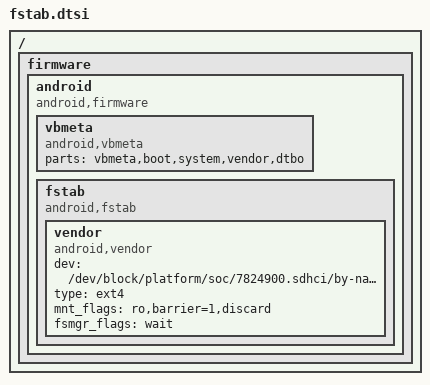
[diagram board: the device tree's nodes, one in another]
/ {
	/delete-node/ firmware;
	firmware: firmware {
		android {
			compatible = "android,firmware";
			vbmeta {
				compatible = "android,vbmeta";
				parts = "vbmeta,boot,system,vendor,dtbo";
			};

			fstab {
				compatible = "android,fstab";
				vendor {
					compatible = "android,vendor";
					dev = "/dev/block/platform/soc/7824900.sdhci/by-name/vendor";
					type = "ext4";
					mnt_flags = "ro,barrier=1,discard";
					fsmgr_flags = "wait";
					status = "ok";
				};
			};
		};
	};
};
